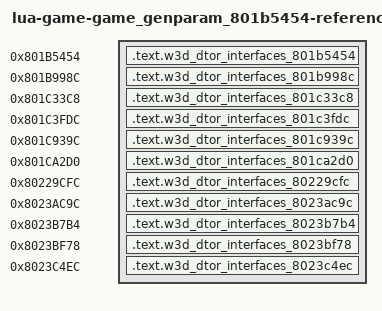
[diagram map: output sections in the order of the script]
/* Generated reference-only placements. All bodies are source-built. */
OUTPUT_FORMAT("elf32-powerpc")
OUTPUT_ARCH(powerpc)
ENTRY(w3d_dtor_interfaces_801b5454)
_SDA_BASE_ = 0x804b2540;
_SDA2_BASE_ = 0x804c2540;
fn_801b4c6c = 0x801b4c6c;
fn_801b8964 = 0x801b8964;
fn_801c9134 = 0x801c9134;
fn_801c939c = 0x801c939c;
fn_801ea138 = 0x801ea138;
fn_801ea740 = 0x801ea740;
fn_8023b5f0 = 0x8023b5f0;
fn_8023b7b4 = 0x8023b7b4;
w3d_vtable_80414528 = 0x80414528;
w3d_vtable_80414c40 = 0x80414c40;
w3d_vtable_80414ce0 = 0x80414ce0;
w3d_vtable_80415618 = 0x80415618;
w3d_vtable_804162d0 = 0x804162d0;
w3d_vtable_80416398 = 0x80416398;
w3d_vtable_8041a0c8 = 0x8041a0c8;
w3d_vtable_8041acc0 = 0x8041acc0;
w3d_vtable_8041ad10 = 0x8041ad10;
w3d_vtable_8041ad88 = 0x8041ad88;
w3d_vtable_8041ae28 = 0x8041ae28;
SECTIONS {
  .text.w3d_dtor_interfaces_801b5454 0x801b5454 : { *(.text.w3d_dtor_interfaces_801b5454) }
  .text.w3d_dtor_interfaces_801b998c 0x801b998c : { *(.text.w3d_dtor_interfaces_801b998c) }
  .text.w3d_dtor_interfaces_801c33c8 0x801c33c8 : { *(.text.w3d_dtor_interfaces_801c33c8) }
  .text.w3d_dtor_interfaces_801c3fdc 0x801c3fdc : { *(.text.w3d_dtor_interfaces_801c3fdc) }
  .text.w3d_dtor_interfaces_801c939c 0x801c939c : { *(.text.w3d_dtor_interfaces_801c939c) }
  .text.w3d_dtor_interfaces_801ca2d0 0x801ca2d0 : { *(.text.w3d_dtor_interfaces_801ca2d0) }
  .text.w3d_dtor_interfaces_80229cfc 0x80229cfc : { *(.text.w3d_dtor_interfaces_80229cfc) }
  .text.w3d_dtor_interfaces_8023ac9c 0x8023ac9c : { *(.text.w3d_dtor_interfaces_8023ac9c) }
  .text.w3d_dtor_interfaces_8023b7b4 0x8023b7b4 : { *(.text.w3d_dtor_interfaces_8023b7b4) }
  .text.w3d_dtor_interfaces_8023bf78 0x8023bf78 : { *(.text.w3d_dtor_interfaces_8023bf78) }
  .text.w3d_dtor_interfaces_8023c4ec 0x8023c4ec : { *(.text.w3d_dtor_interfaces_8023c4ec) }
  /DISCARD/ : { *(.text*) *(.rodata*) *(.data*) *(.bss*) *(.sdata*) *(.sbss*) *(.comment) }
}
